# MB9BF32xT register map
File version: 1.0
CPU: 
Registers are 8-bit, read-write, reset 0x0 unless marked. A register's access mark holds for its fields unless they carry their own. Offsets are from the block's base; [hi:lo] are bit positions; {n}, {i} and the like mark numbered series.

## ADC0 — peripheral ADC0
Base 0x40027000
Same registers: ADC1 0x40027100
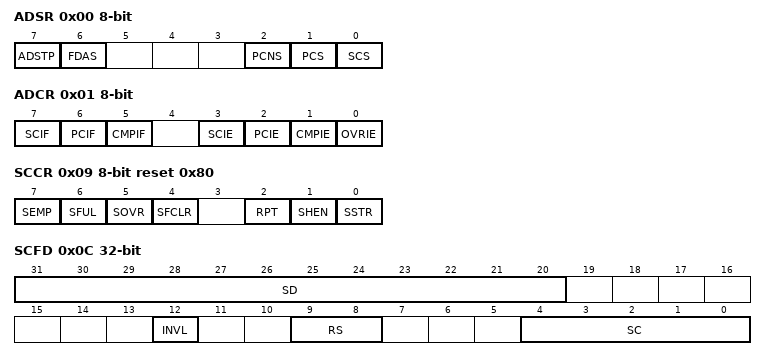
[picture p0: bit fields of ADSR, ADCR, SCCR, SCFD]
0x00 ADSR
  [7] ADSTP, [6] FDAS, [2] PCNS, [1] PCS, [0] SCS
0x01 ADCR
  [7] SCIF, [6] PCIF, [5] CMPIF, [3] SCIE, [2] PCIE, [1] CMPIE, [0] OVRIE
0x08 SFNS
  [3:0] SFS
0x09 SCCR reset 0x80
  [7] SEMP ro, [6] SFUL ro, [5] SOVR, [4] SFCLR, [2] RPT, [1] SHEN, [0] SSTR
0x0C SCFD 32-bit ro
  [31:20] SD, [12] INVL, [9:8] RS, [4:0] SC
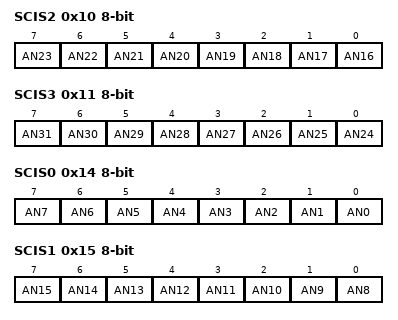
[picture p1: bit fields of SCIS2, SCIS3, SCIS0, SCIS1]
0x10 SCIS2
  [n-16] AN{n} (n=16..23)
0x11 SCIS3
  [n-24] AN{n} (n=24..31)
0x14 SCIS0
  [n] AN{n} (n=0..7)
0x15 SCIS1
  [n-8] AN{n} (n=8..15)
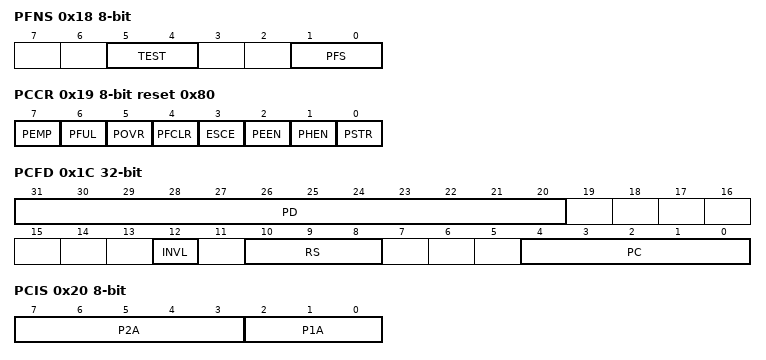
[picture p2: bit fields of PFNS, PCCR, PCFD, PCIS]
0x18 PFNS
  [5:4] TEST ro, [1:0] PFS
0x19 PCCR reset 0x80
  [7] PEMP ro, [6] PFUL ro, [5] POVR, [4] PFCLR, [3] ESCE, [2] PEEN, [1] PHEN, [0] PSTR
0x1C PCFD 32-bit ro
  [31:20] PD, [12] INVL, [10:8] RS, [4:0] PC
0x20 PCIS
  [7:3] P2A, [2:0] P1A
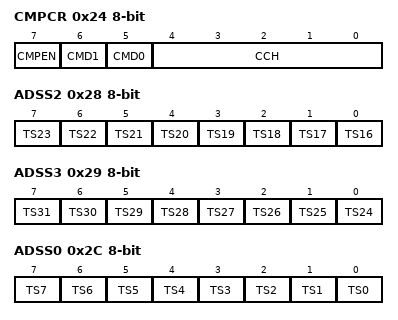
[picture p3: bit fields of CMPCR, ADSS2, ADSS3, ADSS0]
0x24 CMPCR
  [7] CMPEN, [6] CMD1, [5] CMD0, [4:0] CCH
0x26 CMPD 16-bit
  [15:6] CMAD
0x28 ADSS2
  [n-16] TS{n} (n=16..23)
0x29 ADSS3
  [n-24] TS{n} (n=24..31)
0x2C ADSS0
  [n] TS{n} (n=0..7)
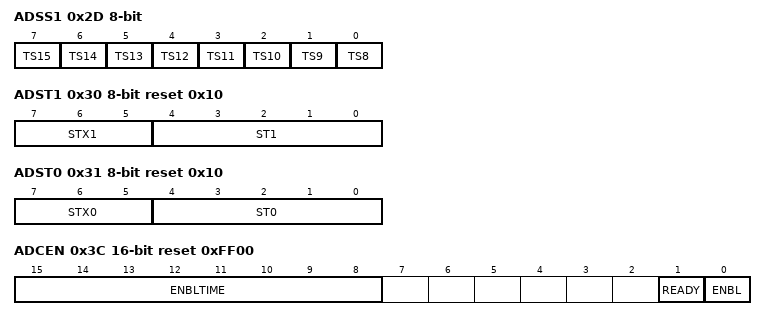
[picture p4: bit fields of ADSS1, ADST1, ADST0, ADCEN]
0x2D ADSS1
  [n-8] TS{n} (n=8..15)
0x30 ADST1 reset 0x10
  [7:5] STX1, [4:0] ST1
0x31 ADST0 reset 0x10
  [7:5] STX0, [4:0] ST0
0x34 ADCT reset 0x7 (reset mask 0x7)
  [7:0] CT
0x38 PRTSL
  [3:0] PRTSL
0x39 SCTSL
  [3:0] SCTSL
0x3C ADCEN 16-bit reset 0xFF00
  [15:8] ENBLTIME, [1] READY ro, [0] ENBL

## DAC — peripheral DAC
Base 0x40028000
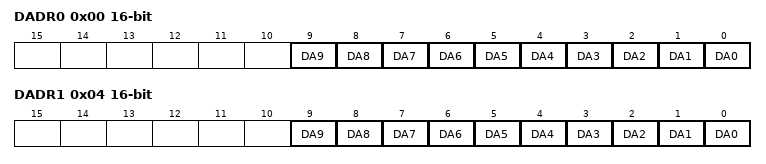
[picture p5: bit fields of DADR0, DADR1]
0x00 DADR0 16-bit reset not defined
  [n] DA{n} (n=0..9)
0x02 DACR0 reset not defined
  [0] DAE
0x04 DADR1 16-bit reset not defined
  [n] DA{n} (n=0..9)
0x06 DACR1 reset not defined
  [0] DAE

## EXTI — peripheral EXTI
Base 0x40030000
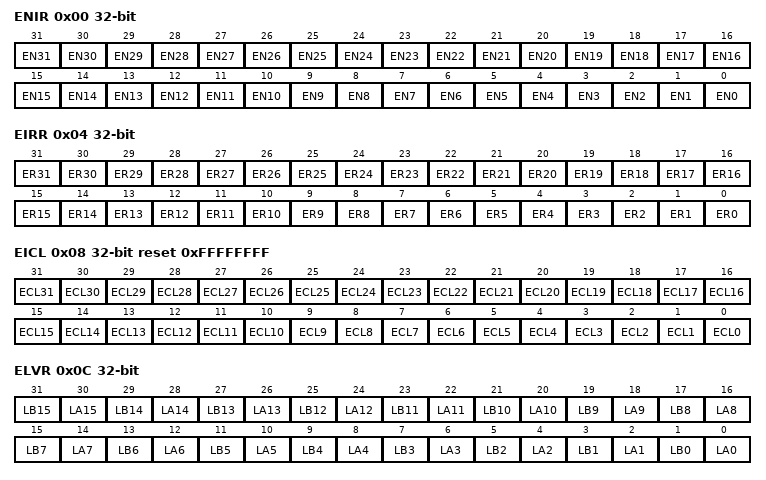
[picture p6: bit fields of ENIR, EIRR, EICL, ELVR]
0x00 ENIR 32-bit
  [n] EN{n} (n=0..31)
0x04 EIRR 32-bit ro reset not defined
  [n] ER{n} (n=0..31)
0x08 EICL 32-bit reset 0xFFFFFFFF
  [n] ECL{n} (n=0..31)
0x0C ELVR 32-bit
  [2n+1] LB{n} (n=0..15), [2n] LA{n} (n=0..15)
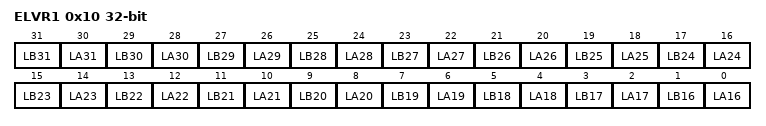
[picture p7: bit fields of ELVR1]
0x10 ELVR1 32-bit
  [2n-31] LB{n} (n=16..31), [2n-32] LA{n} (n=16..31)
0x14 NMIRR ro
  [0] NR
0x18 NMICL reset 0x1
  [0] NCL

## INTREQ — peripheral INTREQ
Base 0x40031000
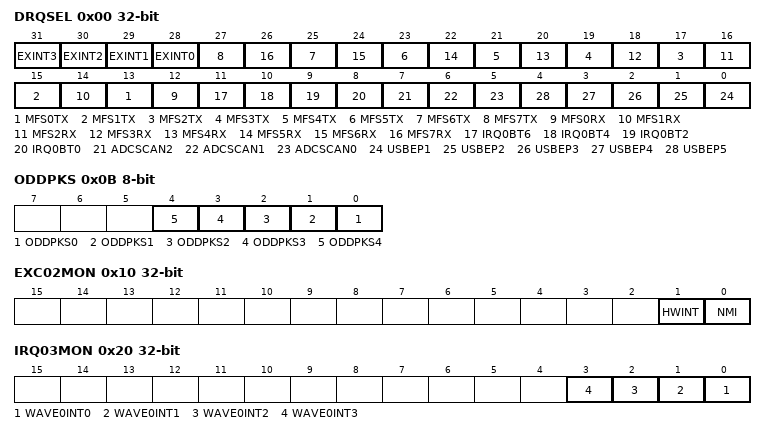
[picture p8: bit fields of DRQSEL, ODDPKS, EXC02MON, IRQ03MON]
0x00 DRQSEL 32-bit
  [n+28] EXINT{n} (n=0..3), [2n+13] MFS{n}TX (n=0..7), [2n+12] MFS{n}RX (n=0..7), [11] IRQ0BT6, [10] IRQ0BT4, [9] IRQ0BT2, [8] IRQ0BT0, [7] ADCSCAN2, [6] ADCSCAN1, [5] ADCSCAN0, [n-1] USBEP{n} (n=1..5)
0x0B ODDPKS
  [n] ODDPKS{n} (n=0..4)
0x0C IRQCMODE 32-bit
  [0] IRQCMODE
0x10 EXC02MON 32-bit ro
  [1] HWINT, [0] NMI
0x14 IRQ00MON 32-bit ro
  [0] FCSINT
0x18 IRQ01MON 32-bit ro
  [0] SWWDTINT
0x1C IRQ02MON 32-bit ro
  [0] LVDINT
0x20 IRQ03MON 32-bit ro
  [n] WAVE0INT{n} (n=0..3)
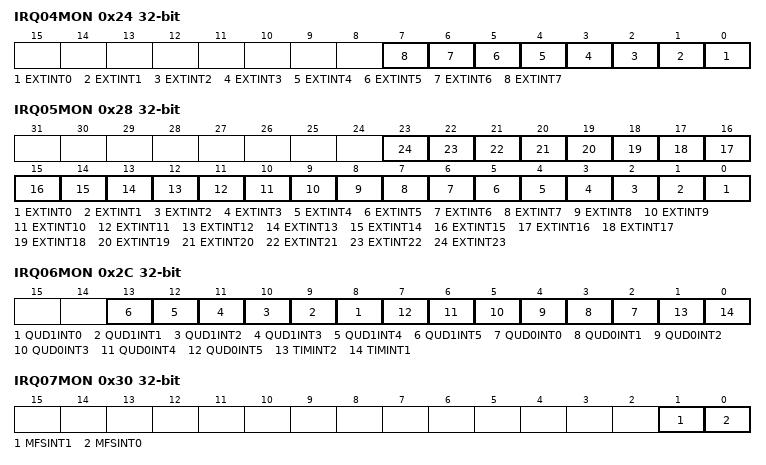
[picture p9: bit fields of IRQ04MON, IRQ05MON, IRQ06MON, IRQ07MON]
0x24 IRQ04MON 32-bit ro
  [n] EXTINT{n} (n=0..7)
0x28 IRQ05MON 32-bit ro
  [n] EXTINT{n} (n=0..23)
0x2C IRQ06MON 32-bit ro
  [n+8] QUD1INT{n} (n=0..5), [n+2] QUD0INT{n} (n=0..5), [1] TIMINT2, [0] TIMINT1
0x30 IRQ07MON 32-bit ro
  [1] MFSINT1, [0] MFSINT0
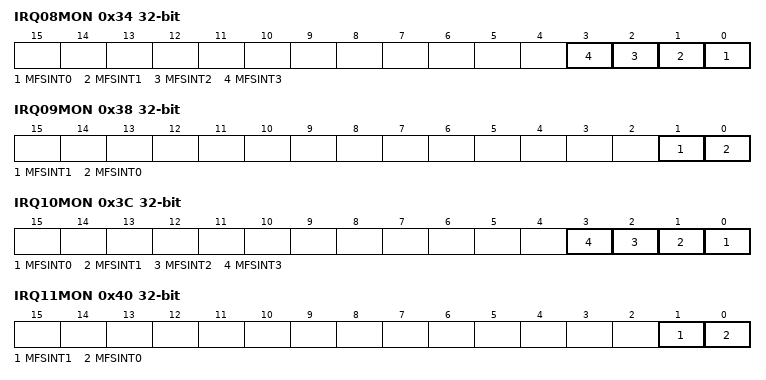
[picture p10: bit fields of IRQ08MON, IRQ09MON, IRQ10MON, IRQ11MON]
0x34 IRQ08MON 32-bit ro
  [n] MFSINT{n} (n=0..3)
0x38 IRQ09MON 32-bit ro
  [1] MFSINT1, [0] MFSINT0
0x3C IRQ10MON 32-bit ro
  [n] MFSINT{n} (n=0..3)
0x40 IRQ11MON 32-bit ro
  [1] MFSINT1, [0] MFSINT0
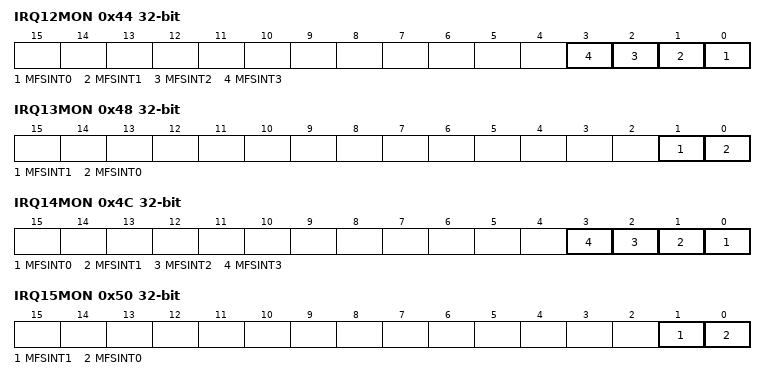
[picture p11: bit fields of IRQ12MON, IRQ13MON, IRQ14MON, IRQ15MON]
0x44 IRQ12MON 32-bit ro
  [n] MFSINT{n} (n=0..3)
0x48 IRQ13MON 32-bit ro
  [1] MFSINT1, [0] MFSINT0
0x4C IRQ14MON 32-bit ro
  [n] MFSINT{n} (n=0..3)
0x50 IRQ15MON 32-bit ro
  [1] MFSINT1, [0] MFSINT0
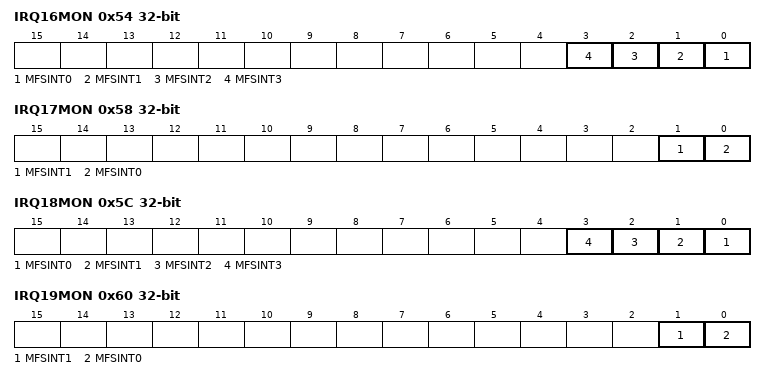
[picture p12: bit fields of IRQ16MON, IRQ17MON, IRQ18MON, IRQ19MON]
0x54 IRQ16MON 32-bit ro
  [n] MFSINT{n} (n=0..3)
0x58 IRQ17MON 32-bit ro
  [1] MFSINT1, [0] MFSINT0
0x5C IRQ18MON 32-bit ro
  [n] MFSINT{n} (n=0..3)
0x60 IRQ19MON 32-bit ro
  [1] MFSINT1, [0] MFSINT0
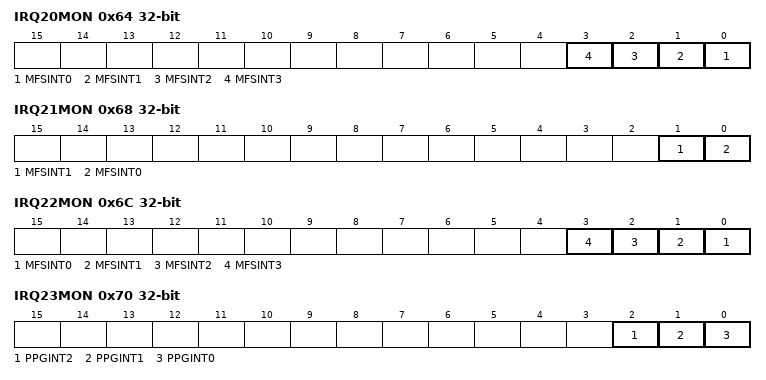
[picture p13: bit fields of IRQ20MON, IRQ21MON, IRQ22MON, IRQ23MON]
0x64 IRQ20MON 32-bit ro
  [n] MFSINT{n} (n=0..3)
0x68 IRQ21MON 32-bit ro
  [1] MFSINT1, [0] MFSINT0
0x6C IRQ22MON 32-bit ro
  [n] MFSINT{n} (n=0..3)
0x70 IRQ23MON 32-bit ro
  [2] PPGINT2, [1] PPGINT1, [0] PPGINT0
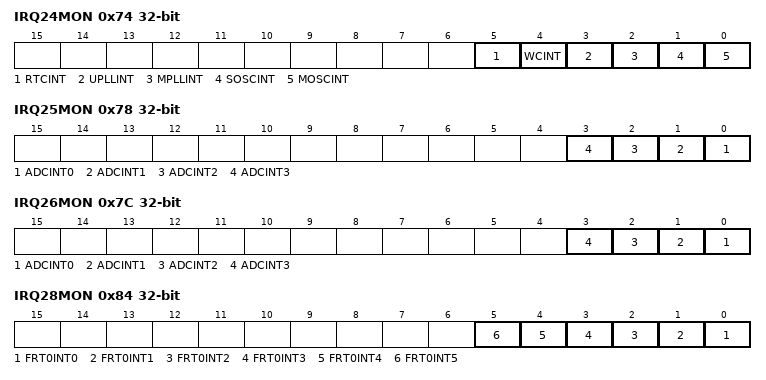
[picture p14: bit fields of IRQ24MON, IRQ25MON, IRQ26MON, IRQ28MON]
0x74 IRQ24MON 32-bit ro
  [5] RTCINT, [4] WCINT, [3] UPLLINT, [2] MPLLINT, [1] SOSCINT, [0] MOSCINT
0x78 IRQ25MON 32-bit ro
  [n] ADCINT{n} (n=0..3)
0x7C IRQ26MON 32-bit ro
  [n] ADCINT{n} (n=0..3)
0x80 IRQ27MON 32-bit ro reset not defined
0x84 IRQ28MON 32-bit ro
  [n] FRT0INT{n} (n=0..5)
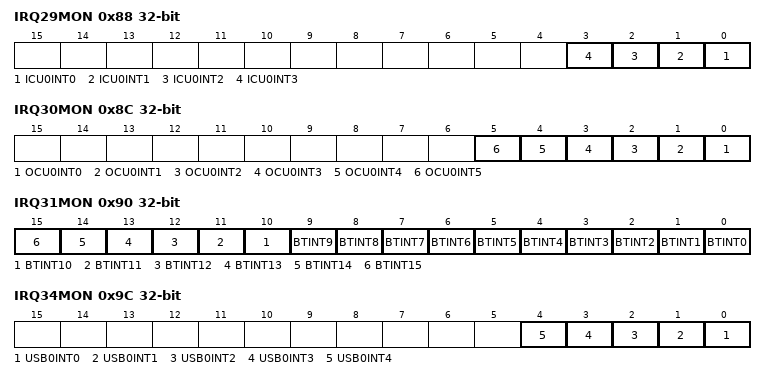
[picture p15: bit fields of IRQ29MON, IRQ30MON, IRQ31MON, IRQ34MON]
0x88 IRQ29MON 32-bit ro
  [n] ICU0INT{n} (n=0..3)
0x8C IRQ30MON 32-bit ro
  [n] OCU0INT{n} (n=0..5)
0x90 IRQ31MON 32-bit ro
  [n] BTINT{n} (n=0..15)
0x94 IRQ32MON 32-bit ro reset not defined
0x98 IRQ33MON 32-bit ro reset not defined
0x9C IRQ34MON 32-bit ro
  [n] USB0INT{n} (n=0..4)
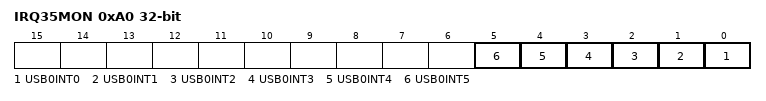
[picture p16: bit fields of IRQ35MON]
0xA0 IRQ35MON 32-bit ro
  [n] USB0INT{n} (n=0..5)
0xA4 IRQ36MON 32-bit ro
  [5] RCEC0INT
0xA8 IRQ37MON 32-bit ro
  [6] RCEC1INT
{0x14+4i} IRQ{i}MON 32-bit ro (i=38..45)
  [0] DMAINT
0xCC IRQ46MON 32-bit ro
  [n] BTINT{n} (n=0..15)
0xD0 IRQ47MON 32-bit ro
  [11] FLASHINT
0x210 RCINTSEL0 32-bit
  [8n+7:8n] INTSEL{n} (n=0..3)
0x214 RCINTSEL1 32-bit
  [8n-25:8n-32] INTSEL{n} (n=4..7)
